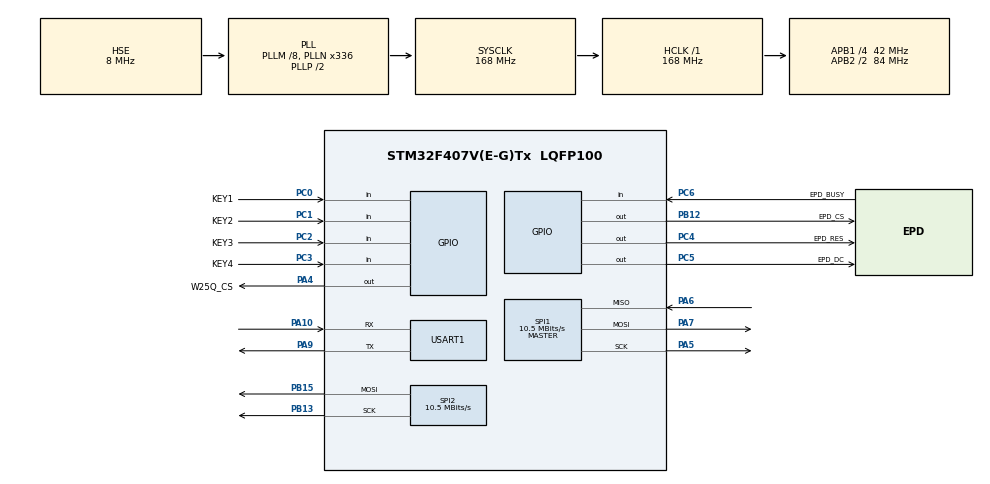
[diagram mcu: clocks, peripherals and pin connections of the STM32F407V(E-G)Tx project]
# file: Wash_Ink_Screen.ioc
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Dma.Request0=SPI1_TX
Dma.Request1=SPI2_TX
Dma.SPI1_TX.0.Direction=DMA_MEMORY_TO_PERIPH
Dma.SPI1_TX.0.FIFOMode=DMA_FIFOMODE_DISABLE
Dma.SPI1_TX.0.Instance=DMA2_Stream3
Dma.SPI1_TX.0.MemDataAlignment=DMA_MDATAALIGN_BYTE
Dma.SPI1_TX.0.MemInc=DMA_MINC_ENABLE
Dma.SPI1_TX.0.Mode=DMA_NORMAL
Dma.SPI1_TX.0.PeriphDataAlignment=DMA_PDATAALIGN_BYTE
Dma.SPI1_TX.0.PeriphInc=DMA_PINC_DISABLE
Dma.SPI1_TX.0.Priority=DMA_PRIORITY_LOW
Dma.SPI2_TX.1.Direction=DMA_MEMORY_TO_PERIPH
Dma.SPI2_TX.1.FIFOMode=DMA_FIFOMODE_DISABLE
Dma.SPI2_TX.1.Instance=DMA1_Stream4
Dma.SPI2_TX.1.MemDataAlignment=DMA_MDATAALIGN_BYTE
Dma.SPI2_TX.1.MemInc=DMA_MINC_ENABLE
Dma.SPI2_TX.1.Mode=DMA_NORMAL
Dma.SPI2_TX.1.PeriphDataAlignment=DMA_PDATAALIGN_BYTE
Dma.SPI2_TX.1.PeriphInc=DMA_PINC_DISABLE
Dma.SPI2_TX.1.Priority=DMA_PRIORITY_LOW
FREERTOS.Tasks01=defaultTask,24,128,StartDefaultTask,Default,NULL,Dynamic,NULL,NULL
FREERTOS.configTOTAL_HEAP_SIZE=20480
Mcu.Family=STM32F4
Mcu.Name=STM32F407V(E-G)Tx
Mcu.Package=LQFP100
NVIC.DMA1_Stream4_IRQn=true\:6\:0\:true\:false\:true\:true\:false\:true\:true
NVIC.DMA2_Stream3_IRQn=true\:6\:0\:true\:false\:true\:true\:false\:true\:true
NVIC.PriorityGroup=NVIC_PRIORITYGROUP_4
NVIC.TIM6_DAC_IRQn=true\:15\:0\:false\:false\:true\:false\:false\:true\:true
NVIC.TimeBase=TIM6_DAC_IRQn
NVIC.TimeBaseIP=TIM6
PA10.Mode=Asynchronous
PA10.Signal=USART1_RX
PA13.Mode=Serial_Wire
PA13.Signal=SYS_JTMS-SWDIO
PA14.Mode=Serial_Wire
PA14.Signal=SYS_JTCK-SWCLK
PA4.GPIO_Label=W25Q_CS
PA4.PinState=GPIO_PIN_SET
PA4.Signal=GPIO_Output
PA5.Mode=Full_Duplex_Master
PA5.Signal=SPI1_SCK
PA6.Mode=Full_Duplex_Master
PA6.Signal=SPI1_MISO
PA7.Mode=Full_Duplex_Master
PA7.Signal=SPI1_MOSI
PA9.Mode=Asynchronous
PA9.Signal=USART1_TX
PB12.GPIO_Label=EPD_CS
PB12.PinState=GPIO_PIN_SET
PB12.Signal=GPIO_Output
PB13.Mode=TX_Only_Simplex_Unidirect_Master
PB13.Signal=SPI2_SCK
PB15.Mode=TX_Only_Simplex_Unidirect_Master
PB15.Signal=SPI2_MOSI
PC0.GPIO_Label=KEY1
PC0.GPIO_PuPd=GPIO_PULLUP
PC0.Signal=GPIO_Input
PC1.GPIO_Label=KEY2
PC1.GPIO_PuPd=GPIO_PULLUP
PC1.Signal=GPIO_Input
PC2.GPIO_Label=KEY3
PC2.GPIO_PuPd=GPIO_PULLUP
PC2.Signal=GPIO_Input
PC3.GPIO_Label=KEY4
PC3.GPIO_PuPd=GPIO_PULLUP
PC3.Signal=GPIO_Input
PC4.GPIO_Label=EPD_RES
PC4.PinState=GPIO_PIN_SET
PC4.Signal=GPIO_Output
PC5.GPIO_Label=EPD_DC
PC5.PinState=GPIO_PIN_RESET
PC5.Signal=GPIO_Output
PC6.GPIO_Label=EPD_BUSY
PC6.Signal=GPIO_Input
PH0-OSC_IN.Mode=HSE-External-Oscillator
PH0-OSC_IN.Signal=RCC_OSC_IN
PH1-OSC_OUT.Mode=HSE-External-Oscillator
PH1-OSC_OUT.Signal=RCC_OSC_OUT
ProjectManager.HeapSize=0x200
ProjectManager.StackSize=0x400
ProjectManager.TargetToolchain=CMake
RCC.48MHZClocksFreq_Value=84000000
RCC.AHBFreq_Value=168000000
RCC.APB1CLKDivider=RCC_HCLK_DIV4
RCC.APB1Freq_Value=42000000
RCC.APB1TimFreq_Value=84000000
RCC.APB2CLKDivider=RCC_HCLK_DIV2
RCC.APB2Freq_Value=84000000
RCC.APB2TimFreq_Value=168000000
RCC.CortexFreq_Value=168000000
RCC.HCLKFreq_Value=168000000
RCC.HSE_VALUE=8000000
RCC.HSI_VALUE=16000000
RCC.LSE_VALUE=32768
RCC.PLLM=8
RCC.PLLN=336
RCC.PLLSourceVirtual=RCC_PLLSOURCE_HSE
RCC.SYSCLKFreq_VALUE=168000000
RCC.SYSCLKSource=RCC_SYSCLKSOURCE_PLLCLK
RCC.VCOOutputFreq_Value=336000000
SPI1.BaudRatePrescaler=SPI_BAUDRATEPRESCALER_8
SPI1.CalculateBaudRate=10.5 MBits/s
SPI1.Direction=SPI_DIRECTION_2LINES
SPI1.Mode=SPI_MODE_MASTER
SPI1.VirtualType=VM_MASTER
SPI2.BaudRatePrescaler=SPI_BAUDRATEPRESCALER_4
SPI2.CalculateBaudRate=10.5 MBits/s
SPI2.Direction=SPI_DIRECTION_2LINES
SPI2.Mode=SPI_MODE_MASTER
SPI2.VirtualType=VM_MASTER
USART1.VirtualMode=VM_ASYNC
VP_FREERTOS_VS_CMSIS_V2.Mode=CMSIS_V2
VP_SYS_VS_tim6.Mode=TIM6
board=custom

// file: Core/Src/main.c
/* USER CODE BEGIN Header */
/**
  ******************************************************************************
  * @file           : main.c
  * @brief          : Main program body
  ******************************************************************************
  * @attention
  *
  * Copyright (c) 2026 STMicroelectronics.
  * All rights reserved.
  *
  * This software is licensed under terms that can be found in the LICENSE file
  * in the root directory of this software component.
  * If no LICENSE file comes with this software, it is provided AS-IS.
  *
  ******************************************************************************
  */
/* USER CODE END Header */
#include "main.h"
#include "cmsis_os.h"

/* USER CODE BEGIN Includes */
#include "spi_bsp.h"
#include "w25q128_test.h"
/* USER CODE END Includes */

SPI_HandleTypeDef hspi1;
SPI_HandleTypeDef hspi2;
DMA_HandleTypeDef hdma_spi1_tx;
DMA_HandleTypeDef hdma_spi2_tx;

UART_HandleTypeDef huart1;

/* Definitions for defaultTask */
osThreadId_t defaultTaskHandle;
const osThreadAttr_t defaultTask_attributes = {
  .name = "defaultTask",
  .stack_size = 512 * 4,   /* 2KB，printf 内部缓冲约需 256B，留足余量 */
  .priority = (osPriority_t) osPriorityNormal,
};

void SystemClock_Config(void);
static void MX_GPIO_Init(void);
static void MX_DMA_Init(void);
static void MX_SPI1_Init(void);
static void MX_SPI2_Init(void);
static void MX_USART1_UART_Init(void);
void StartDefaultTask(void *argument);

int main(void)
{

  /* MCU Configuration--------------------------------------------------------*/

  /* Reset of all peripherals, Initializes the Flash interface and the Systick. */
  HAL_Init();

  /* Configure the system clock */
  SystemClock_Config();

  /* Initialize all configured peripherals */
  MX_GPIO_Init();
  MX_DMA_Init();
  MX_SPI1_Init();
  MX_SPI2_Init();
  MX_USART1_UART_Init();
  /* USER CODE BEGIN 2 */
  SPI_BSP_Init();   /* create DMA semaphores for SPI1 and SPI2 */
  /* USER CODE END 2 */

  /* Init scheduler */
  osKernelInitialize();

  /* Create the thread(s) */
  /* creation of defaultTask */
  defaultTaskHandle = osThreadNew(StartDefaultTask, NULL, &defaultTask_attributes);

  /* Start scheduler */
  osKernelStart();

  /* We should never get here as control is now taken by the scheduler */

  /* Infinite loop */
  while (1)
  {

  }
}

void SystemClock_Config(void)
{
  RCC_OscInitTypeDef RCC_OscInitStruct = {0};
  RCC_ClkInitTypeDef RCC_ClkInitStruct = {0};

  /** Configure the main internal regulator output voltage
  */
  __HAL_RCC_PWR_CLK_ENABLE();
  __HAL_PWR_VOLTAGESCALING_CONFIG(PWR_REGULATOR_VOLTAGE_SCALE1);

  /** Initializes the RCC Oscillators according to the specified parameters
  * in the RCC_OscInitTypeDef structure.
  */
  RCC_OscInitStruct.OscillatorType = RCC_OSCILLATORTYPE_HSE;
  RCC_OscInitStruct.HSEState = RCC_HSE_ON;
  RCC_OscInitStruct.PLL.PLLState = RCC_PLL_ON;
  RCC_OscInitStruct.PLL.PLLSource = RCC_PLLSOURCE_HSE;
  RCC_OscInitStruct.PLL.PLLM = 8;
  RCC_OscInitStruct.PLL.PLLN = 336;
  RCC_OscInitStruct.PLL.PLLP = RCC_PLLP_DIV2;
  RCC_OscInitStruct.PLL.PLLQ = 4;
  if (HAL_RCC_OscConfig(&RCC_OscInitStruct) != HAL_OK)
  {
    Error_Handler();
  }

  /** Initializes the CPU, AHB and APB buses clocks
  */
  RCC_ClkInitStruct.ClockType = RCC_CLOCKTYPE_HCLK|RCC_CLOCKTYPE_SYSCLK
                              |RCC_CLOCKTYPE_PCLK1|RCC_CLOCKTYPE_PCLK2;
  RCC_ClkInitStruct.SYSCLKSource = RCC_SYSCLKSOURCE_PLLCLK;
  RCC_ClkInitStruct.AHBCLKDivider = RCC_SYSCLK_DIV1;
  RCC_ClkInitStruct.APB1CLKDivider = RCC_HCLK_DIV4;
  RCC_ClkInitStruct.APB2CLKDivider = RCC_HCLK_DIV2;

  if (HAL_RCC_ClockConfig(&RCC_ClkInitStruct, FLASH_LATENCY_5) != HAL_OK)
  {
    Error_Handler();
  }
}

static void MX_SPI1_Init(void)
{

  /* SPI1 parameter configuration*/
  hspi1.Instance = SPI1;
  hspi1.Init.Mode = SPI_MODE_MASTER;
  hspi1.Init.Direction = SPI_DIRECTION_2LINES;
  hspi1.Init.DataSize = SPI_DATASIZE_8BIT;
  hspi1.Init.CLKPolarity = SPI_POLARITY_LOW;
  hspi1.Init.CLKPhase = SPI_PHASE_1EDGE;
  hspi1.Init.NSS = SPI_NSS_SOFT;
  hspi1.Init.BaudRatePrescaler = SPI_BAUDRATEPRESCALER_8;
  hspi1.Init.FirstBit = SPI_FIRSTBIT_MSB;
  hspi1.Init.TIMode = SPI_TIMODE_DISABLE;
  hspi1.Init.CRCCalculation = SPI_CRCCALCULATION_DISABLE;
  hspi1.Init.CRCPolynomial = 10;
  if (HAL_SPI_Init(&hspi1) != HAL_OK)
  {
    Error_Handler();
  }

}

static void MX_SPI2_Init(void)
{

  /* SPI2 parameter configuration*/
  hspi2.Instance = SPI2;
  hspi2.Init.Mode = SPI_MODE_MASTER;
  hspi2.Init.Direction = SPI_DIRECTION_2LINES;
  hspi2.Init.DataSize = SPI_DATASIZE_8BIT;
  hspi2.Init.CLKPolarity = SPI_POLARITY_LOW;
  hspi2.Init.CLKPhase = SPI_PHASE_1EDGE;
  hspi2.Init.NSS = SPI_NSS_SOFT;
  hspi2.Init.BaudRatePrescaler = SPI_BAUDRATEPRESCALER_4;
  hspi2.Init.FirstBit = SPI_FIRSTBIT_MSB;
  hspi2.Init.TIMode = SPI_TIMODE_DISABLE;
  hspi2.Init.CRCCalculation = SPI_CRCCALCULATION_DISABLE;
  hspi2.Init.CRCPolynomial = 10;
  if (HAL_SPI_Init(&hspi2) != HAL_OK)
  {
    Error_Handler();
  }

}

static void MX_USART1_UART_Init(void)
{

  huart1.Instance = USART1;
  huart1.Init.BaudRate = 115200;
  huart1.Init.WordLength = UART_WORDLENGTH_8B;
  huart1.Init.StopBits = UART_STOPBITS_1;
  huart1.Init.Parity = UART_PARITY_NONE;
  huart1.Init.Mode = UART_MODE_TX_RX;
  huart1.Init.HwFlowCtl = UART_HWCONTROL_NONE;
  huart1.Init.OverSampling = UART_OVERSAMPLING_16;
  if (HAL_UART_Init(&huart1) != HAL_OK)
  {
    Error_Handler();
  }

}

static void MX_DMA_Init(void)
{

  /* DMA controller clock enable */
  __HAL_RCC_DMA2_CLK_ENABLE();
  __HAL_RCC_DMA1_CLK_ENABLE();

  /* DMA interrupt init */
  /* DMA1_Stream4_IRQn interrupt configuration */
  HAL_NVIC_SetPriority(DMA1_Stream4_IRQn, 6, 0);
  HAL_NVIC_EnableIRQ(DMA1_Stream4_IRQn);
  /* DMA2_Stream3_IRQn interrupt configuration */
  HAL_NVIC_SetPriority(DMA2_Stream3_IRQn, 6, 0);
  HAL_NVIC_EnableIRQ(DMA2_Stream3_IRQn);

}

static void MX_GPIO_Init(void)
{
  GPIO_InitTypeDef GPIO_InitStruct = {0};

  /* GPIO Ports Clock Enable */
  __HAL_RCC_GPIOH_CLK_ENABLE();
  __HAL_RCC_GPIOC_CLK_ENABLE();
  __HAL_RCC_GPIOA_CLK_ENABLE();
  __HAL_RCC_GPIOB_CLK_ENABLE();

  /*Configure GPIO pin Output Level */
  HAL_GPIO_WritePin(W25Q_CS_GPIO_Port, W25Q_CS_Pin, GPIO_PIN_SET);

  /*Configure GPIO pin Output Level */
  HAL_GPIO_WritePin(EPD_RES_GPIO_Port, EPD_RES_Pin, GPIO_PIN_SET);

  /*Configure GPIO pin Output Level */
  HAL_GPIO_WritePin(EPD_DC_GPIO_Port, EPD_DC_Pin, GPIO_PIN_RESET);

  /*Configure GPIO pin Output Level */
  HAL_GPIO_WritePin(EPD_CS_GPIO_Port, EPD_CS_Pin, GPIO_PIN_SET);

  /*Configure GPIO pins : KEY1_Pin KEY2_Pin KEY3_Pin KEY4_Pin */
  GPIO_InitStruct.Pin = KEY1_Pin|KEY2_Pin|KEY3_Pin|KEY4_Pin;
  GPIO_InitStruct.Mode = GPIO_MODE_INPUT;
  GPIO_InitStruct.Pull = GPIO_PULLUP;
  HAL_GPIO_Init(GPIOC, &GPIO_InitStruct);

  /*Configure GPIO pin : W25Q_CS_Pin */
  GPIO_InitStruct.Pin = W25Q_CS_Pin;
  GPIO_InitStruct.Mode = GPIO_MODE_OUTPUT_PP;
  GPIO_InitStruct.Pull = GPIO_NOPULL;
  GPIO_InitStruct.Speed = GPIO_SPEED_FREQ_LOW;
  HAL_GPIO_Init(W25Q_CS_GPIO_Port, &GPIO_InitStruct);

  /*Configure GPIO pins : EPD_RES_Pin EPD_DC_Pin */
  GPIO_InitStruct.Pin = EPD_RES_Pin|EPD_DC_Pin;
  GPIO_InitStruct.Mode = GPIO_MODE_OUTPUT_PP;
  GPIO_InitStruct.Pull = GPIO_NOPULL;
  GPIO_InitStruct.Speed = GPIO_SPEED_FREQ_LOW;
  HAL_GPIO_Init(GPIOC, &GPIO_InitStruct);

  /*Configure GPIO pin : EPD_CS_Pin */
  GPIO_InitStruct.Pin = EPD_CS_Pin;
  GPIO_InitStruct.Mode = GPIO_MODE_OUTPUT_PP;
  GPIO_InitStruct.Pull = GPIO_NOPULL;
  GPIO_InitStruct.Speed = GPIO_SPEED_FREQ_LOW;
  HAL_GPIO_Init(EPD_CS_GPIO_Port, &GPIO_InitStruct);

  /*Configure GPIO pin : EPD_BUSY_Pin */
  GPIO_InitStruct.Pin = EPD_BUSY_Pin;
  GPIO_InitStruct.Mode = GPIO_MODE_INPUT;
  GPIO_InitStruct.Pull = GPIO_NOPULL;
  HAL_GPIO_Init(EPD_BUSY_GPIO_Port, &GPIO_InitStruct);

}

void StartDefaultTask(void *argument)
{
  /* USER CODE BEGIN 5 */
  W25Q128_Test_Run();   /* 内部含无限循环，不会返回 */
  /* USER CODE END 5 */
}

void HAL_TIM_PeriodElapsedCallback(TIM_HandleTypeDef *htim)
{
  if (htim->Instance == TIM6)
  {
    HAL_IncTick();
  }
}

void Error_Handler(void)
{
  __disable_irq();
  while (1)
  {
  }
}
